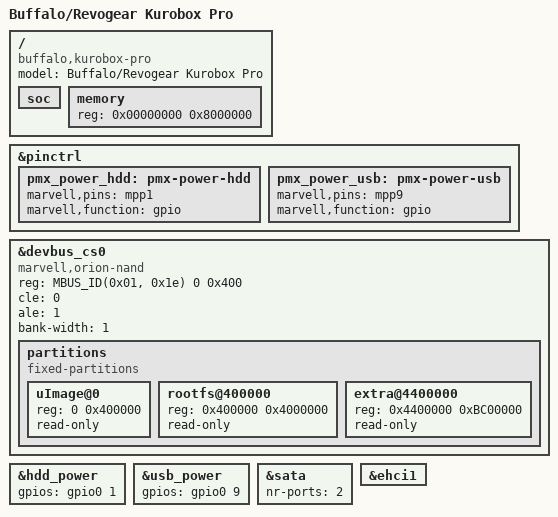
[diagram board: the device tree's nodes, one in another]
/dts-v1/;
#include "orion5x-linkstation.dtsi"
#include <dt-bindings/gpio/gpio.h>
/ {
	model = "Buffalo/Revogear Kurobox Pro";
	compatible = "buffalo,kurobox-pro", "marvell,orion5x-88f5182", "marvell,orion5x";
	soc {
		ranges = <MBUS_ID(0xf0, 0x01) 0 0xf1000000 0x100000>,
				 <MBUS_ID(0x09, 0x00) 0 0xf2200000 0x800>,
				 <MBUS_ID(0x01, 0x0f) 0 0xf4000000 0x40000>,
				 <MBUS_ID(0x01, 0x1e) 0 0xfc000000 0x1000000>;
	};
	memory {  
		device_type = "memory";
		reg = <0x00000000 0x8000000>;
	};
};
&pinctrl {
	pmx_power_hdd: pmx-power-hdd {
		marvell,pins = "mpp1";
		marvell,function = "gpio";
	};
	pmx_power_usb: pmx-power-usb {
		marvell,pins = "mpp9";
		marvell,function = "gpio";
	};
};
&devbus_cs0 {
	status = "okay";
	compatible = "marvell,orion-nand";
	reg = <MBUS_ID(0x01, 0x1e) 0 0x400>;
	cle = <0>;
	ale = <1>;
	bank-width = <1>;
	partitions {
		compatible = "fixed-partitions";
		#address-cells = <1>;
		#size-cells = <1>;
		uImage@0 {  
			reg = <0 0x400000>;
			read-only;
		};
		rootfs@400000 {  
			reg = <0x400000 0x4000000>;
			read-only;
		};
		extra@4400000 {  
			reg = <0x4400000 0xBC00000>;
			read-only;
		};
	};
};
&hdd_power {
	gpios = <&gpio0 1 GPIO_ACTIVE_HIGH>;
};
&usb_power {
	gpios = <&gpio0 9 GPIO_ACTIVE_HIGH>;
};
&sata {
	nr-ports = <2>;
};
&ehci1 {
	status = "okay";
};
